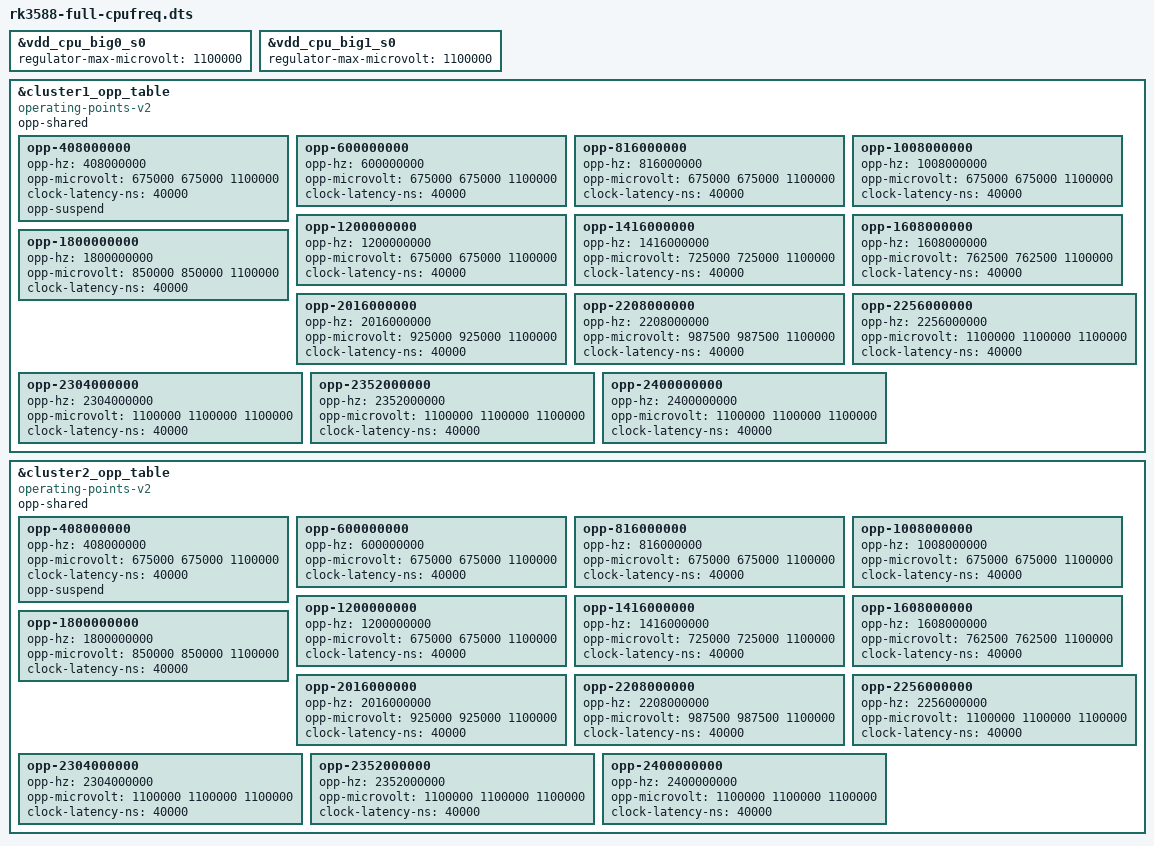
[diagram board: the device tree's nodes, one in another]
/dts-v1/;
/plugin/;
/ {
	fragment@0 {
		target = <&vdd_cpu_big0_s0>;
		__overlay__ {
			regulator-max-microvolt = <1100000>;
		};
	};

	fragment@1 {
		target = <&vdd_cpu_big1_s0>;
		__overlay__ {
			regulator-max-microvolt = <1100000>;
		};
	};

	fragment@2 {
		target = <&cluster1_opp_table>;
		__overlay__ {
			compatible = "operating-points-v2";
			opp-shared;

			opp-408000000 {
				opp-hz = /bits/ 64 <408000000>;
				opp-microvolt = <675000 675000 1100000>;
				clock-latency-ns = <40000>;
				opp-suspend;
			};
			opp-600000000 {
				opp-hz = /bits/ 64 <600000000>;
				opp-microvolt = <675000 675000 1100000>;
				clock-latency-ns = <40000>;
			};
			opp-816000000 {
				opp-hz = /bits/ 64 <816000000>;
				opp-microvolt = <675000 675000 1100000>;
				clock-latency-ns = <40000>;
			};
			opp-1008000000 {
				opp-hz = /bits/ 64 <1008000000>;
				opp-microvolt = <675000 675000 1100000>;
				clock-latency-ns = <40000>;
			};
			opp-1200000000 {
				opp-hz = /bits/ 64 <1200000000>;
				opp-microvolt = <675000 675000 1100000>;
				clock-latency-ns = <40000>;
			};
			opp-1416000000 {
				opp-hz = /bits/ 64 <1416000000>;
				opp-microvolt = <725000 725000 1100000>;
				clock-latency-ns = <40000>;
			};
			opp-1608000000 {
				opp-hz = /bits/ 64 <1608000000>;
				opp-microvolt = <762500 762500 1100000>;
				clock-latency-ns = <40000>;
			};
			opp-1800000000 {
				opp-hz = /bits/ 64 <1800000000>;
				opp-microvolt = <850000 850000 1100000>;
				clock-latency-ns = <40000>;
			};
			opp-2016000000 {
				opp-hz = /bits/ 64 <2016000000>;
				opp-microvolt = <925000 925000 1100000>;
				clock-latency-ns = <40000>;
			};
			opp-2208000000 {
				opp-hz = /bits/ 64 <2208000000>;
				opp-microvolt = <987500 987500 1100000>;
				clock-latency-ns = <40000>;
			};
			opp-2256000000 {
				opp-hz = /bits/ 64 <2256000000>;
				opp-microvolt = <1100000 1100000 1100000>;
				clock-latency-ns = <40000>;
			};
			opp-2304000000 {
				opp-hz = /bits/ 64 <2304000000>;
				opp-microvolt = <1100000 1100000 1100000>;
				clock-latency-ns = <40000>;
			};
			opp-2352000000 {
				opp-hz = /bits/ 64 <2352000000>;
				opp-microvolt = <1100000 1100000 1100000>;
				clock-latency-ns = <40000>;
			};
			opp-2400000000 {
				opp-hz = /bits/ 64 <2400000000>;
				opp-microvolt = <1100000 1100000 1100000>;
				clock-latency-ns = <40000>;
			};
		};
	};

	fragment@3 {
		target = <&cluster2_opp_table>;
		__overlay__ {
			compatible = "operating-points-v2";
			opp-shared;

			opp-408000000 {
				opp-hz = /bits/ 64 <408000000>;
				opp-microvolt = <675000 675000 1100000>;
				clock-latency-ns = <40000>;
				opp-suspend;
			};
			opp-600000000 {
				opp-hz = /bits/ 64 <600000000>;
				opp-microvolt = <675000 675000 1100000>;
				clock-latency-ns = <40000>;
			};
			opp-816000000 {
				opp-hz = /bits/ 64 <816000000>;
				opp-microvolt = <675000 675000 1100000>;
				clock-latency-ns = <40000>;
			};
			opp-1008000000 {
				opp-hz = /bits/ 64 <1008000000>;
				opp-microvolt = <675000 675000 1100000>;
				clock-latency-ns = <40000>;
			};
			opp-1200000000 {
				opp-hz = /bits/ 64 <1200000000>;
				opp-microvolt = <675000 675000 1100000>;
				clock-latency-ns = <40000>;
			};
			opp-1416000000 {
				opp-hz = /bits/ 64 <1416000000>;
				opp-microvolt = <725000 725000 1100000>;
				clock-latency-ns = <40000>;
			};
			opp-1608000000 {
				opp-hz = /bits/ 64 <1608000000>;
				opp-microvolt = <762500 762500 1100000>;
				clock-latency-ns = <40000>;
			};
			opp-1800000000 {
				opp-hz = /bits/ 64 <1800000000>;
				opp-microvolt = <850000 850000 1100000>;
				clock-latency-ns = <40000>;
			};
			opp-2016000000 {
				opp-hz = /bits/ 64 <2016000000>;
				opp-microvolt = <925000 925000 1100000>;
				clock-latency-ns = <40000>;
			};
			opp-2208000000 {
				opp-hz = /bits/ 64 <2208000000>;
				opp-microvolt = <987500 987500 1100000>;
				clock-latency-ns = <40000>;
			};
			opp-2256000000 {
				opp-hz = /bits/ 64 <2256000000>;
				opp-microvolt = <1100000 1100000 1100000>;
				clock-latency-ns = <40000>;
			};
			opp-2304000000 {
				opp-hz = /bits/ 64 <2304000000>;
				opp-microvolt = <1100000 1100000 1100000>;
				clock-latency-ns = <40000>;
			};
			opp-2352000000 {
				opp-hz = /bits/ 64 <2352000000>;
				opp-microvolt = <1100000 1100000 1100000>;
				clock-latency-ns = <40000>;
			};
			opp-2400000000 {
				opp-hz = /bits/ 64 <2400000000>;
				opp-microvolt = <1100000 1100000 1100000>;
				clock-latency-ns = <40000>;
			};
		};
	};
};
